# ATUC64D3 device description
Architecture: AVR32_UC3; Family: AVR UC3
Registers are 32-bit, read-write, reset 0x0 unless marked. A register's access mark holds for its fields unless they carry their own. Offsets are from the block's base; [hi:lo] are bit positions; lines under a group give offsets from that group; {n}, {i} and the like mark numbered series; 'fields as' and 'values as' point back to an identical list.

## FREQM — Frequency Meter
Instances: FREQM 0xffff5c00
0x00 CTRL wo — Control register
  [0] START — Start frequency measurement
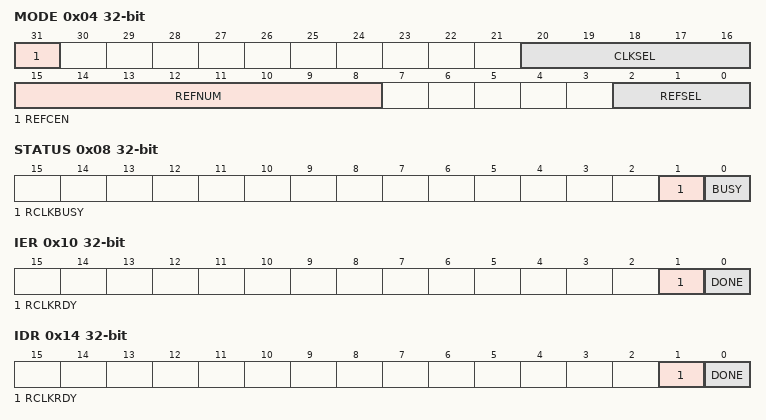
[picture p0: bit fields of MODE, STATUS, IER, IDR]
0x04 MODE
  [31] REFCEN — Reference Clock Enable
  [20:16] CLKSEL — Clock Source Selection
  [15:8] REFNUM — Number of Reference CLock Cycles
  [2:0] REFSEL — Reference Clock Selection
0x08 STATUS ro
  [1] RCLKBUSY — Reference Clock Busy
  [0] BUSY — Frequency measurement on-going
0x0C VALUE ro
  [23:0] VALUE — Measured frequency
0x10 IER wo — Interrupt Enable Register
  [1] RCLKRDY — Reference Clock ready
  [0] DONE — Frequency measurment done
0x14 IDR wo — Interrupt Diable Register
  fields as IER
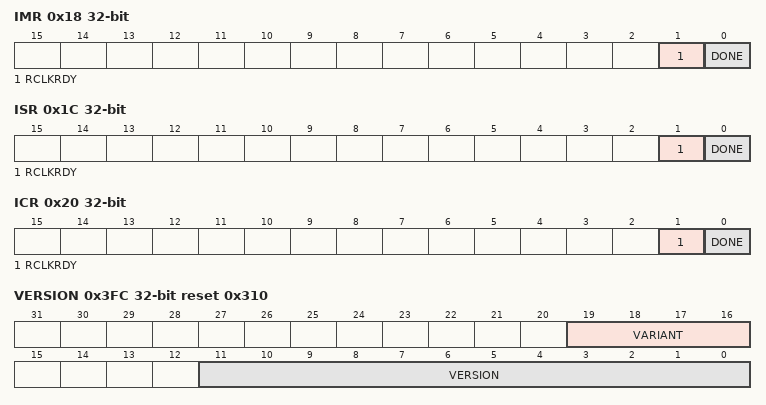
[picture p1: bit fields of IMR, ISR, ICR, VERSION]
0x18 IMR ro — Interrupt Mask Register
  fields as IER
0x1C ISR ro — Interrupt Status Register
  fields as IER
0x20 ICR wo — Interrupt Clear Register
  fields as IER
0x3FC VERSION ro reset 0x310
  [19:16] VARIANT — Variant number
  [11:0] VERSION — Version number

## USERPAGE_FUSES — Fuses
Instances: USERPAGE_FUSES 0x80800000
0x00 USERPAGE_WORD_0 reset 0xFFFFFFFF
  [0] WDTAUTO — Watch dog timer auto enable/disable at startup
    0=WDT_ENABLE (Watch dog timer is automatically enabled at startup); 1=WDT_DISABLE (Watch dog timer is not automatically enabled at startup)

## FLASH_FUSES — Fuses
Instances: FUSES 0xFFFE1400 in fuses
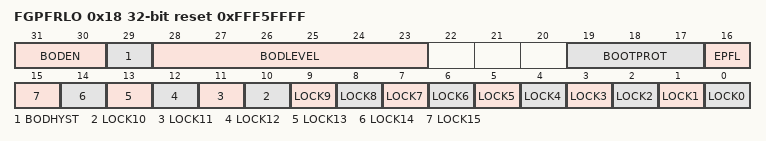
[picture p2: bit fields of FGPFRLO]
0x18 FGPFRLO reset 0xFFF5FFFF — Flash Controller General Purpose Fuse Register Low
  [31:30] BODEN — Brownout detector enable
    0=BOD_DISABLED; 1=BOD_ENABLED_RESET_ENABLED (BOD enabled, BOD reset enabled); 2=BOD_ENABLED_RESET_DISABLED (BOD enabled, BOD reset disabled); 3=BOD_DISABLED2
  [29] BODHYST — Brownout detector hysteresis
    0=BODHYST_DISABLED (Disabled); 1=BODHYST_ENABLED (Enabled)
  [28:23] BODLEVEL — Brownout detector trigger level
    0=BOD_LEVEL_1V44 (BOD Level 1.44V); 23=BOD_LEVEL_1V52 (BOD Level 1.52V); 31=BOD_LEVEL_1V61 (BOD Level 1.61V); 39=BOD_LEVEL_1V71 (BOD Level 1.71V)
  [19:17] BOOTPROT — Bootloader protection
    0=BOOTAREA_32KB (Boot area: 32 Kbyte); 1=BOOTAREA_16KB (Boot area: 16 Kbyte); 2=BOOTAREA_8KB (Boot area: 8 Kbyte); 3=BOOTAREA_4KB (Boot area: 4 Kbyte); 4=BOOTAREA_2KB (Boot area: 2 Kbyte); 5=BOOTAREA_1KB (Boot area: 1 Kbyte); 6=BOOTAREA_512B (Boot area: 512 bytes); 7=BOOTAREA_0B (Boot area: 0 byte)
  [16] EPFL — External privileged fetch lock
    0=EPFL_LOCK (External privileged fetch locked); 1=EPFL_NO_LOCK (External privileged fetch not locked)
  [n] LOCK{n} (n=0..15)

## GLOC — Glue Logic Controller
Instances: GLOC 0xffff6400
{0x0+8i} LUT[{i}] (i=0..6) group
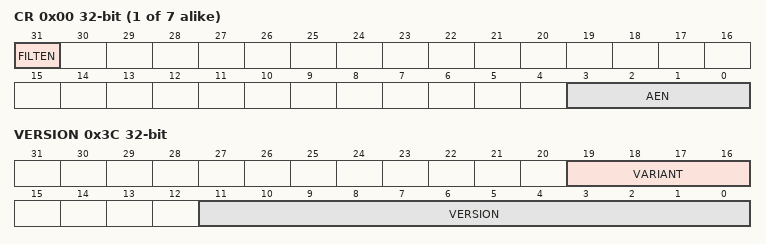
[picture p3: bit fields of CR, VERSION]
  0x00 CR — Control Register
    [31] FILTEN — Filter enable
    [3:0] AEN — Input mask
  0x04 TRUTH
    [15:0] TRUTH
0x38 PARAMETER ro reset not defined
  [7:0] LUTS
0x3C VERSION ro reset not defined
  [19:16] VARIANT, [11:0] VERSION

## GPIO_LOCAL — Local Bus Mapped GPIO Registers
Instances: GPIO_LOCAL 0x40000000
Parameters: PORT_LENGTH=AVR32_GPIO_PORT_LENGTH
{0x0+0x100*i} port[{i}] (i=0..63) group
  0x40 ODERW wo reset not defined — Output Driver Enable Register - Write
  0x44 ODERS wo reset not defined — Output Driver Enable Register - Set
  0x48 ODERC wo reset not defined — Output Driver Enable Register - Clear
  0x4C ODERT wo reset not defined — Output Driver Enable Register - Toggle
  0x50 OVRW wo reset not defined — Output Value Register - Write
  0x54 OVRS wo reset not defined — Output Value Register - Set
  0x58 OVRC wo reset not defined — Output Value Register - Clear
  0x5C OVRT wo reset not defined — Output Value Register - Toggle
  0x60 PVR ro reset not defined — Pin Value Register

## HMATRIXB — HSB Matrix
Instances: HMATRIXB 0xfffe1000
{0x0+4i} mcfg[{i}] (i=0..15) access not given reset 0x2
  [2:0] ULBT — Undefined Length Burst Type
    0=INFINITE; 1=SINGLE; 2=FOUR_BEAT; 3=EIGHT_BEAT; 4=SIXTEEN_BEAT
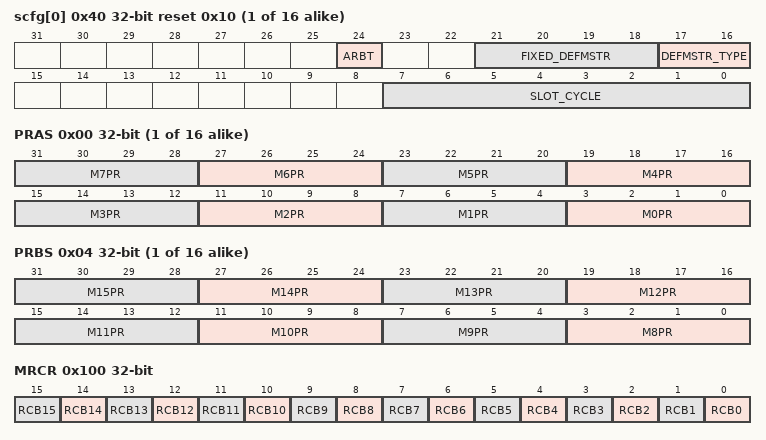
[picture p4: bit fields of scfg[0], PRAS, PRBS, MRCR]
{0x40+4i} scfg[{i}] (i=0..15) access not given reset 0x10
  [24] ARBT — Arbitration Type
    0=ROUND_ROBIN; 1=FIXED_PRIORITY
  [21:18] FIXED_DEFMSTR — Fixed Index of Default Master
  [17:16] DEFMSTR_TYPE — Default Master Type
    0=NO_DEFAULT; 1=LAST_DEFAULT; 2=FIXED_DEFAULT
  [7:0] SLOT_CYCLE — Maximum Number of Allowed Cycles for a Burst
{0x80+8i} prs[{i}] (i=0..15) group
  0x00 PRAS — Priority Register A for Slave 0
    [4n+3:4n] M{n}PR (n=0..7) — Master {n} Priority
  0x04 PRBS — Priority Register B for Slave 0
    [4n-29:4n-32] M{n}PR (n=8..15) — Master {n} Priority
0x100 MRCR — Master Remap Control Register
  [n] RCB{n} (n=0..15) — Remap Command bit for Master {n}
{0x110+4i} sfr[{i}] (i=0..15) access not given
  [31:0] SFR — Special Function Register
